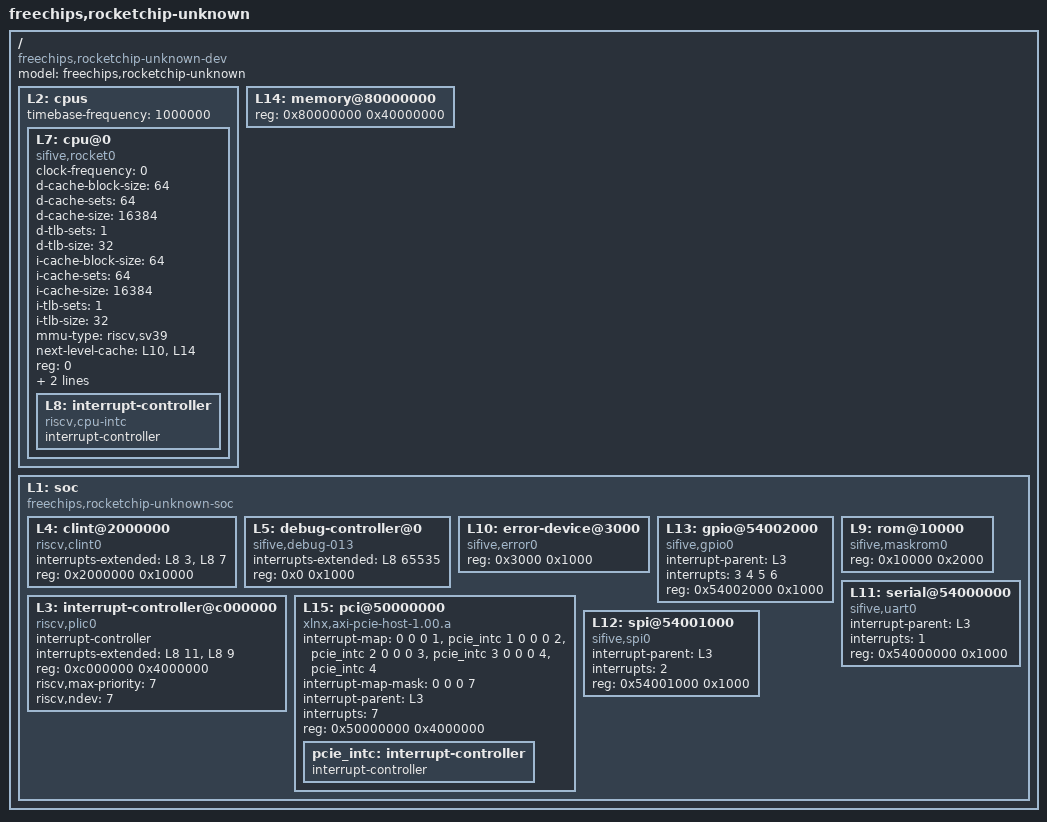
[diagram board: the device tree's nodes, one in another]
/dts-v1/;

/ {
	#address-cells = <1>;
	#size-cells = <1>;
	compatible = "freechips,rocketchip-unknown-dev";
	model = "freechips,rocketchip-unknown";
	L2: cpus {
		#address-cells = <1>;
		#size-cells = <0>;
		timebase-frequency = <1000000>;
		L7: cpu@0 {
			clock-frequency = <0>;
			compatible = "sifive,rocket0", "riscv";
			d-cache-block-size = <64>;
			d-cache-sets = <64>;
			d-cache-size = <16384>;
			d-tlb-sets = <1>;
			d-tlb-size = <32>;
			device_type = "cpu";
			i-cache-block-size = <64>;
			i-cache-sets = <64>;
			i-cache-size = <16384>;
			i-tlb-sets = <1>;
			i-tlb-size = <32>;
			mmu-type = "riscv,sv39";
			next-level-cache = <&L10 &L14>;
			reg = <0>;
			riscv,isa = "rv64imac";
			status = "okay";
			tlb-split;
			L8: interrupt-controller {
				#interrupt-cells = <1>;
				compatible = "riscv,cpu-intc";
				interrupt-controller;
			};
		};
	};
	L14: memory@80000000 {
		device_type = "memory";
		reg = <0x80000000 0x40000000>;
	};
	L1: soc {
		#address-cells = <1>;
		#size-cells = <1>;
		compatible = "freechips,rocketchip-unknown-soc", "simple-bus";
		ranges;
		L4: clint@2000000 {
			compatible = "riscv,clint0";
			interrupts-extended = <&L8 3 &L8 7>;
			reg = <0x2000000 0x10000>;
			reg-names = "control";
		};
		L5: debug-controller@0 {
			compatible = "sifive,debug-013", "riscv,debug-013";
			interrupts-extended = <&L8 65535>;
			reg = <0x0 0x1000>;
			reg-names = "control";
		};
		L10: error-device@3000 {
			compatible = "sifive,error0";
			reg = <0x3000 0x1000>;
			reg-names = "mem";
		};
		L13: gpio@54002000 {
			compatible = "sifive,gpio0";
			interrupt-parent = <&L3>;
			interrupts = <3 4 5 6>;
			reg = <0x54002000 0x1000>;
			reg-names = "control";
		};
		L3: interrupt-controller@c000000 {
			#interrupt-cells = <1>;
			compatible = "riscv,plic0";
			interrupt-controller;
			interrupts-extended = <&L8 11 &L8 9>;
			reg = <0xc000000 0x4000000>;
			reg-names = "control";
			riscv,max-priority = <7>;
			riscv,ndev = <7>;
		};
		L15: pci@50000000 {
			#address-cells = <3>;
			#interrupt-cells = <1>;
			#size-cells = <2>;
			compatible = "xlnx,axi-pcie-host-1.00.a";
			device_type = "pci";
			interrupt-map = <0 0 0 1 &pcie_intc 1 0 0 0 2 &pcie_intc 2 0 0 0 3 &pcie_intc 3 0 0 0 4 &pcie_intc 4>;
			interrupt-map-mask = <0 0 0 7>;
			interrupt-parent = <&L3>;
			interrupts = <7>;
			ranges = <0x2000000 0x0 0x60000000 0x60000000 0x0 0x20000000>;
			reg = <0x50000000 0x4000000>;
			reg-names = "control";
			pcie_intc: interrupt-controller {
				#address-cells = <0>;
				#interrupt-cells = <1>;
				interrupt-controller;
			};
		};
		L9: rom@10000 {
			compatible = "sifive,maskrom0";
			reg = <0x10000 0x2000>;
			reg-names = "mem";
		};
		L11: serial@54000000 {
			compatible = "sifive,uart0";
			interrupt-parent = <&L3>;
			interrupts = <1>;
			reg = <0x54000000 0x1000>;
			reg-names = "control";
		};
		L12: spi@54001000 {
			compatible = "sifive,spi0";
			interrupt-parent = <&L3>;
			interrupts = <2>;
			reg = <0x54001000 0x1000>;
			reg-names = "control";
		};
	};
};
